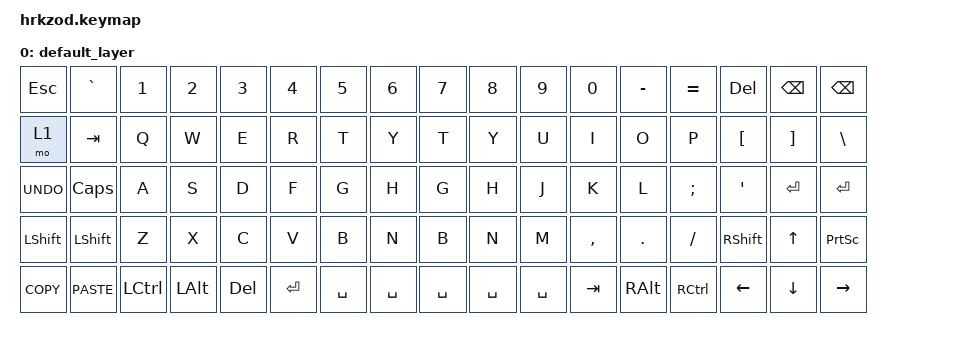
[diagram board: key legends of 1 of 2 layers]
/*
 * Copyright (c) 2020 The ZMK Contributors
 *
 * SPDX-License-Identifier: MIT
 */

#include <behaviors.dtsi>
#include <dt-bindings/zmk/bt.h>
#include <dt-bindings/zmk/keys.h>

/ {
    keymap {
        compatible = "zmk,keymap";

        default_layer {
            bindings = <
&kp ESC         &kp GRAVE    &kp N1     &kp N2    &kp N3   &kp N4     &kp N5     &kp N6     &kp N7     &kp N8     &kp N9     &kp N0     &kp MINUS  &kp EQUAL  &kp DEL    &kp BSPC   &kp BSPC
&mo 1           &kp TAB      &kp Q      &kp W     &kp E    &kp R      &kp T      &kp Y      &kp T      &kp Y      &kp U      &kp I      &kp O      &kp P      &kp LBKT   &kp RBKT   &kp BSLH
&kp K_UNDO      &kp CAPS     &kp A      &kp S     &kp D    &kp F      &kp G      &kp H      &kp G      &kp H      &kp J      &kp K      &kp L      &kp SEMI   &kp APOS   &kp ENTER  &kp ENTER
&kp LEFT_SHIFT  &kp LSHFT    &kp Z      &kp X     &kp C    &kp V      &kp B      &kp N      &kp B      &kp N      &kp M      &kp COMMA  &kp DOT    &kp SLASH  &kp RSHFT  &kp UP     &kp PSCRN
&kp K_COPY      &kp K_PASTE  &kp LCTRL  &kp LALT  &kp DEL  &kp ENTER  &kp SPACE  &kp SPACE  &kp SPACE  &kp SPACE  &kp SPACE  &kp TAB    &kp RALT   &kp RCTRL  &kp LEFT   &kp DOWN   &kp RIGHT
            >;

            sensor-bindings = <&inc_dec_kp C_VOL_UP C_VOL_DN &inc_dec_kp PG_UP PG_DN>;
        };

        lower_layer {
            // ------------------------------------------------------------------------------------------------------------
            // |       | F1  | F2  |  F3  |  F4  |  F5  |                                  |  F6  |  F7   |  F8   |  F9  |  F10  |  F11  |
            // | N.LC  |  7  |  8  |   9  |PRTSC | SCRLK|        |                 |       | PAUSE|       |   7   |   8  |   9   |  F12  |
            // |       |  4  |  5  |   6  | INS  | HOME |        |                 |       |  PGUP|       |   4   |   5  |   6   |       |
            // |       |  1  |  2  |   3  | DEL  |  END |        |       | |       |       |  PGDN|       |   1   |   2  |   3   |       |
            // |       |  0  |  .  | Enter|      |               |       | |       |              |       |   0   |   .  | Enter |       |

            bindings = <
&mo 1        &kp F1     &kp F2     &kp F3     &kp F4     &kp F5      &kp F6        &kp F7     &kp F8     &kp F9     &kp F10    &kp F11       &kp F12      &bt BT_CLR  &bt BT_SEL 0  &bt BT_SEL 1  &bt BT_SEL 2
&kp KP_NUM   &kp KP_N7  &kp KP_N8  &kp KP_N9  &kp PSCRN  &kp SLCK    &trans        &trans     &trans     &trans     &kp KP_N7  &kp KP_N8     &kp KP_N9    &trans      &bt BT_SEL 3  &sys_reset    &bt BT_SEL 3
&sys_reset   &kp KP_N6  &kp INS    &kp HOME   &trans     &trans      &kp PG_UP     &trans     &kp KP_N4  &kp KP_N5  &kp KP_N6  &bt BT_SEL 4  &bootloader  &kp KP_N1   &kp KP_N2     &kp KP_N3     &bt BT_SEL 4
&bootloader  &trans     &trans     &trans     &trans     &kp PG_DN   &trans        &kp KP_N1  &kp KP_N2  &kp KP_N3  &trans     &trans        &kp KP_N0    &kp KP_DOT  &kp KP_ENTER  &trans        &trans
&trans       &trans     &trans     &trans     &kp KP_N0  &kp KP_DOT  &kp KP_ENTER  &trans
            >;

            sensor-bindings = <&inc_dec_kp C_VOL_UP C_VOL_DN &inc_dec_kp PG_UP PG_DN>;
        };
    };
};
